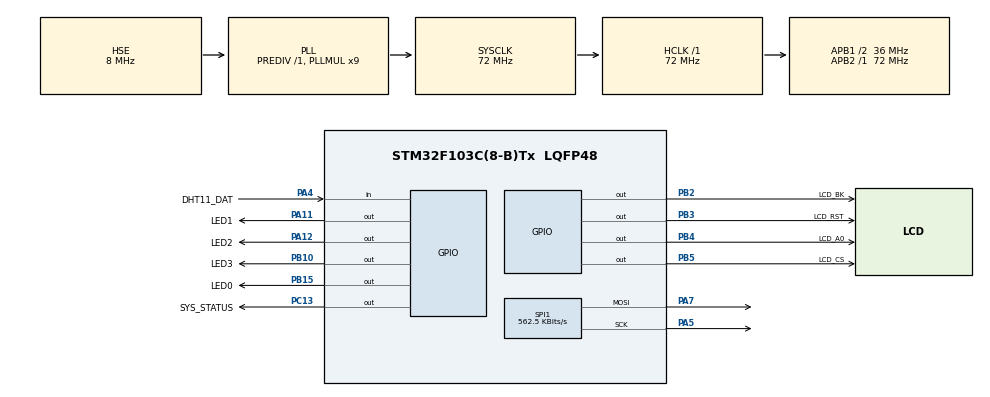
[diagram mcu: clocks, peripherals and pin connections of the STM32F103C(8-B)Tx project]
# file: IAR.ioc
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Mcu.Family=STM32F1
Mcu.Name=STM32F103C(8-B)Tx
Mcu.Package=LQFP48
NVIC.PriorityGroup=NVIC_PRIORITYGROUP_4
NVIC.TIM2_IRQn=true\:1\:0\:true\:false\:true\:true\:true
PA11.GPIO_Label=LED1
PA11.GPIO_Speed=GPIO_SPEED_FREQ_HIGH
PA11.PinState=GPIO_PIN_SET
PA11.Signal=GPIO_Output
PA12.GPIO_Label=LED2
PA12.GPIO_Speed=GPIO_SPEED_FREQ_HIGH
PA12.PinState=GPIO_PIN_SET
PA12.Signal=GPIO_Output
PA13.Mode=Serial_Wire
PA13.Signal=SYS_JTMS-SWDIO
PA14.Mode=Serial_Wire
PA14.Signal=SYS_JTCK-SWCLK
PA4.GPIO_Label=DHT11_DAT
PA4.Signal=GPIO_Input
PA5.Mode=TX_Only_Simplex_Unidirect_Master
PA5.Signal=SPI1_SCK
PA7.Mode=TX_Only_Simplex_Unidirect_Master
PA7.Signal=SPI1_MOSI
PB10.GPIO_Label=LED3
PB10.GPIO_Speed=GPIO_SPEED_FREQ_HIGH
PB10.PinState=GPIO_PIN_SET
PB10.Signal=GPIO_Output
PB15.GPIO_Label=LED0
PB15.GPIO_Speed=GPIO_SPEED_FREQ_HIGH
PB15.PinState=GPIO_PIN_SET
PB15.Signal=GPIO_Output
PB2.GPIO_Label=LCD_BK
PB2.GPIO_Speed=GPIO_SPEED_FREQ_HIGH
PB2.PinState=GPIO_PIN_SET
PB2.Signal=GPIO_Output
PB3.GPIO_Label=LCD_RST
PB3.GPIO_Speed=GPIO_SPEED_FREQ_HIGH
PB3.PinState=GPIO_PIN_SET
PB3.Signal=GPIO_Output
PB4.GPIO_Label=LCD_A0
PB4.GPIO_Speed=GPIO_SPEED_FREQ_HIGH
PB4.PinState=GPIO_PIN_SET
PB4.Signal=GPIO_Output
PB5.GPIO_Label=LCD_CS
PB5.GPIO_Speed=GPIO_SPEED_FREQ_HIGH
PB5.PinState=GPIO_PIN_SET
PB5.Signal=GPIO_Output
PC13-TAMPER-RTC.GPIO_Label=SYS_STATUS
PC13-TAMPER-RTC.GPIO_Speed=GPIO_SPEED_FREQ_HIGH
PC13-TAMPER-RTC.PinState=GPIO_PIN_SET
PC13-TAMPER-RTC.Signal=GPIO_Output
PD0-OSC_IN.Mode=HSE-External-Oscillator
PD0-OSC_IN.Signal=RCC_OSC_IN
PD1-OSC_OUT.Mode=HSE-External-Oscillator
PD1-OSC_OUT.Signal=RCC_OSC_OUT
ProjectManager.HeapSize=0x200
ProjectManager.StackSize=0x400
ProjectManager.TargetToolchain=EWARM V8
RCC.AHBFreq_Value=72000000
RCC.APB1CLKDivider=RCC_HCLK_DIV2
RCC.APB1Freq_Value=36000000
RCC.APB1TimFreq_Value=72000000
RCC.APB2Freq_Value=72000000
RCC.APB2TimFreq_Value=72000000
RCC.HCLKFreq_Value=72000000
RCC.PLLMUL=RCC_PLL_MUL9
RCC.PLLSourceVirtual=RCC_PLLSOURCE_HSE
RCC.SYSCLKFreq_VALUE=72000000
RCC.SYSCLKSource=RCC_SYSCLKSOURCE_PLLCLK
RCC.USBFreq_Value=72000000
SPI1.BaudRatePrescaler=SPI_BAUDRATEPRESCALER_128
SPI1.CLKPhase=SPI_PHASE_2EDGE
SPI1.CLKPolarity=SPI_POLARITY_HIGH
SPI1.CalculateBaudRate=562.5 KBits/s
SPI1.Direction=SPI_DIRECTION_2LINES
SPI1.Mode=SPI_MODE_MASTER
SPI1.VirtualType=VM_MASTER
TIM2.Period=5-1
TIM2.Prescaler=71-1
VP_TIM2_VS_ClockSourceINT.Mode=Internal
board=custom

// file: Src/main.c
/* USER CODE BEGIN Header */
/**
******************************************************************************
* @file           : main.c
* @brief          : Main program body
******************************************************************************
* @attention
*
* <h2><center>&copy; Copyright (c) 2019 STMicroelectronics.
* All rights reserved.</center></h2>
*
* This software component is licensed by ST under BSD 3-Clause license,
* the "License"; You may not use this file except in compliance with the
* License. You may obtain a copy of the License at:
*                        opensource.org/licenses/BSD-3-Clause
*
******************************************************************************
*/
/* USER CODE END Header */

#include "main.h"
#include "spi.h"
#include "tim.h"
#include "gpio.h"

/* USER CODE BEGIN Includes */
#include "lcd.h"
#include "led.h"
#include "delay.h"
#include "dht11.h"
/* USER CODE END Includes */

void SystemClock_Config(void);

int main(void)
{

  /* MCU Configuration--------------------------------------------------------*/

  /* Reset of all peripherals, Initializes the Flash interface and the Systick. */
  HAL_Init();

  /* Configure the system clock */
  SystemClock_Config();

  /* Initialize all configured peripherals */
  MX_GPIO_Init();
  MX_TIM2_Init();
  MX_SPI1_Init();
  /* USER CODE BEGIN 2 */
    led_gpio_init();
    Init_ST7567();

  /* USER CODE END 2 */

  /* Infinite loop */
  /* USER CODE BEGIN WHILE */
    while (1)
    {
      HAL_GPIO_WritePin(LED0_GPIO_Port, LED0_Pin, GPIO_PIN_RESET);
      if(dht11_read_data() == 1)
      {
          HAL_GPIO_WritePin(LED0_GPIO_Port, LED0_Pin, GPIO_PIN_SET);
      }
      display_num(0, 2, 1, dht11_buffer[0]);  //湿度
      display_num(2, 2, 1, dht11_buffer[2]);  //温度
      delay_ms(1000);

    /* USER CODE END WHILE */

    }
}

void SystemClock_Config(void)
{
  RCC_OscInitTypeDef RCC_OscInitStruct = {0};
  RCC_ClkInitTypeDef RCC_ClkInitStruct = {0};

  /** Initializes the CPU, AHB and APB busses clocks
  */
  RCC_OscInitStruct.OscillatorType = RCC_OSCILLATORTYPE_HSE;
  RCC_OscInitStruct.HSEState = RCC_HSE_ON;
  RCC_OscInitStruct.HSEPredivValue = RCC_HSE_PREDIV_DIV1;
  RCC_OscInitStruct.HSIState = RCC_HSI_ON;
  RCC_OscInitStruct.PLL.PLLState = RCC_PLL_ON;
  RCC_OscInitStruct.PLL.PLLSource = RCC_PLLSOURCE_HSE;
  RCC_OscInitStruct.PLL.PLLMUL = RCC_PLL_MUL9;
  if (HAL_RCC_OscConfig(&RCC_OscInitStruct) != HAL_OK)
  {
    Error_Handler();
  }
  /** Initializes the CPU, AHB and APB busses clocks
  */
  RCC_ClkInitStruct.ClockType = RCC_CLOCKTYPE_HCLK|RCC_CLOCKTYPE_SYSCLK
                              |RCC_CLOCKTYPE_PCLK1|RCC_CLOCKTYPE_PCLK2;
  RCC_ClkInitStruct.SYSCLKSource = RCC_SYSCLKSOURCE_PLLCLK;
  RCC_ClkInitStruct.AHBCLKDivider = RCC_SYSCLK_DIV1;
  RCC_ClkInitStruct.APB1CLKDivider = RCC_HCLK_DIV2;
  RCC_ClkInitStruct.APB2CLKDivider = RCC_HCLK_DIV1;

  if (HAL_RCC_ClockConfig(&RCC_ClkInitStruct, FLASH_LATENCY_2) != HAL_OK)
  {
    Error_Handler();
  }
}

void Error_Handler(void)
{
}

/************************ (C) COPYRIGHT STMicroelectronics *****END OF FILE****/
